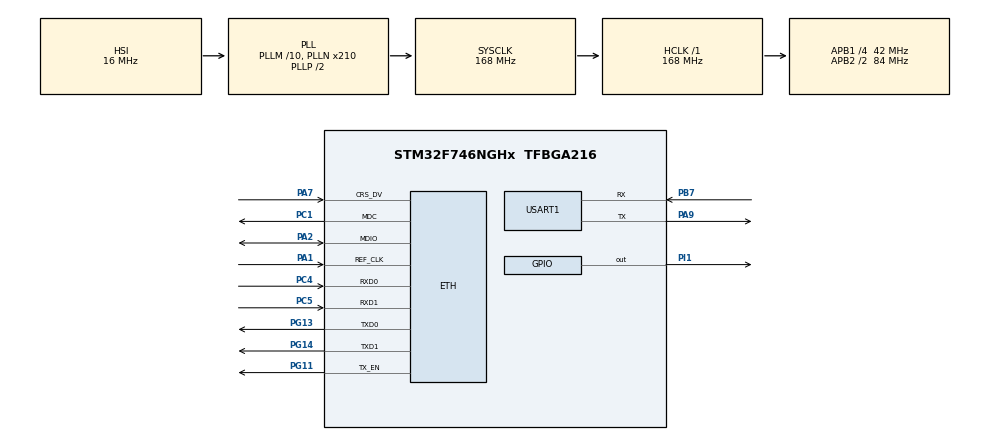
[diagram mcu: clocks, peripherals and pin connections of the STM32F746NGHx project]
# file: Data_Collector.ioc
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ETH.MediaInterface=HAL_ETH_RMII_MODE
FREERTOS.Tasks01=AppControlTask,24,1536,StartAppControlTask,Default,NULL,Dynamic,NULL,NULL;MonitorTask,8,512,StartMonitorTask,Default,NULL,Dynamic,NULL,NULL
FREERTOS.configUSE_NEWLIB_REENTRANT=1
LWIP.BSP.number=1
LWIP.CHECKSUM_BY_HARDWARE=1
LWIP.CHECKSUM_CHECK_ICMP=0
LWIP.CHECKSUM_CHECK_IP=0
LWIP.CHECKSUM_CHECK_TCP=0
LWIP.CHECKSUM_CHECK_UDP=0
LWIP.CHECKSUM_GEN_ICMP=0
LWIP.CHECKSUM_GEN_IP=0
LWIP.CHECKSUM_GEN_TCP=0
LWIP.CHECKSUM_GEN_UDP=0
LWIP.GATEWAY_ADDRESS=192.168.001.001
LWIP.IP_ADDRESS=192.168.001.050
LWIP.LWIP_DHCP=0
LWIP.MEM_SIZE=1600
LWIP.NETMASK_ADDRESS=255.255.255.000
LWIP.TCPIP_THREAD_STACKSIZE=1024
LWIP.Version=v2.1.2_Cube
LWIP0.BSP.STBoard=false
LWIP0.BSP.api=BSP_COMPONENT_DRIVER
LWIP0.BSP.component=LAN8742
LWIP0.BSP.instance=LAN8742
LWIP0.BSP.name=Driver_PHY
LWIP0.BSP.semaphore=S_LAN8742
LWIP0.BSP.solution=LAN8742
Mcu.Family=STM32F7
Mcu.Name=STM32F746NGHx
Mcu.Package=TFBGA216
NVIC.ETH_IRQn=true\:5\:0\:false\:false\:true\:true\:false\:true\:true
NVIC.PriorityGroup=NVIC_PRIORITYGROUP_4
NVIC.TIM6_DAC_IRQn=true\:15\:0\:false\:false\:true\:false\:false\:true\:true
NVIC.TimeBase=TIM6_DAC_IRQn
NVIC.TimeBaseIP=TIM6
PA1.Mode=RMII
PA1.Signal=ETH_REF_CLK
PA13.Mode=Serial_Wire
PA13.Signal=SYS_JTMS-SWDIO
PA14.Mode=Serial_Wire
PA14.Signal=SYS_JTCK-SWCLK
PA2.Mode=RMII
PA2.Signal=ETH_MDIO
PA7.Mode=RMII
PA7.Signal=ETH_CRS_DV
PA9.Mode=Asynchronous
PA9.Signal=USART1_TX
PB7.Mode=Asynchronous
PB7.Signal=USART1_RX
PC1.Mode=RMII
PC1.Signal=ETH_MDC
PC4.Mode=RMII
PC4.Signal=ETH_RXD0
PC5.Mode=RMII
PC5.Signal=ETH_RXD1
PG11.Mode=RMII
PG11.Signal=ETH_TX_EN
PG13.Mode=RMII
PG13.Signal=ETH_TXD0
PG14.Mode=RMII
PG14.Signal=ETH_TXD1
PH0/OSC_IN.Mode=HSE-External-Oscillator
PH0/OSC_IN.Signal=RCC_OSC_IN
PH1/OSC_OUT.Mode=HSE-External-Oscillator
PH1/OSC_OUT.Signal=RCC_OSC_OUT
PI1.Signal=GPIO_Output
ProjectManager.HeapSize=0x200
ProjectManager.StackSize=0x400
ProjectManager.TargetToolchain=STM32CubeIDE
RCC.AHBFreq_Value=168000000
RCC.APB1CLKDivider=RCC_HCLK_DIV4
RCC.APB1Freq_Value=42000000
RCC.APB1TimFreq_Value=84000000
RCC.APB2CLKDivider=RCC_HCLK_DIV2
RCC.APB2Freq_Value=84000000
RCC.APB2TimFreq_Value=168000000
RCC.CortexFreq_Value=168000000
RCC.HCLKFreq_Value=168000000
RCC.HSE_VALUE=25000000
RCC.HSI_VALUE=16000000
RCC.LSE_VALUE=32768
RCC.PLLM=10
RCC.PLLN=210
RCC.PLLSourceVirtual=RCC_PLLSOURCE_HSI
RCC.SYSCLKFreq_VALUE=168000000
RCC.SYSCLKSource=RCC_SYSCLKSOURCE_PLLCLK
RCC.USBFreq_Value=168000000
RCC.VCOOutputFreq_Value=336000000
TIM2.Prescaler=21599
USART1.VirtualMode-Asynchronous=VM_ASYNC
VP_CRC_VS_CRC.Mode=CRC_Activate
VP_FREERTOS_VS_CMSIS_V2.Mode=CMSIS_V2
VP_LWIP_VS_Enabled.Mode=Enabled
VP_SYS_VS_tim6.Mode=TIM6
VP_TIM2_VS_ClockSourceINT.Mode=Internal
board=STM32F746G-DISCO

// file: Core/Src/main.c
/* USER CODE BEGIN Header */
/**
  ******************************************************************************
  * @file           : main.c
  * @brief          : Main program body
  ******************************************************************************
  * @attention
  *
  * Copyright (c) 2026 STMicroelectronics.
  * All rights reserved.
  *
  * This software is licensed under terms that can be found in the LICENSE file
  * in the root directory of this software component.
  * If no LICENSE file comes with this software, it is provided AS-IS.
  *
  ******************************************************************************
  */
/* USER CODE END Header */
#include "main.h"
#include "cmsis_os.h"
#include "crc.h"
#include "lwip.h"
#include "tim.h"
#include "usart.h"
#include "gpio.h"

/* USER CODE BEGIN Includes */
#include <stdio.h>
#include "svc_monitoring.h"
/* USER CODE END Includes */

void SystemClock_Config(void);
void MX_FREERTOS_Init(void);

/* USER CODE BEGIN 0 */
int _write(int file, char *ptr, int len)
{
  HAL_UART_Transmit(&huart1, (const uint8_t *)ptr, len, HAL_MAX_DELAY);

  return len;
}
/* USER CODE END 0 */

int main(void)
{

  /* MCU Configuration--------------------------------------------------------*/

  /* Reset of all peripherals, Initializes the Flash interface and the Systick. */
  HAL_Init();

  /* Configure the system clock */
  SystemClock_Config();

  /* Initialize all configured peripherals */
  MX_GPIO_Init();
  MX_USART1_UART_Init();
  MX_TIM2_Init();
  MX_CRC_Init();
  /* USER CODE BEGIN 2 */
  printf("[INIT] STM32F746G Initilization...\r\n");

  HAL_TIM_Base_Start(&htim2);
  /* USER CODE END 2 */

  /* Init scheduler */
  osKernelInitialize();  /* Call init function for freertos objects (in cmsis_os2.c) */
  MX_FREERTOS_Init();

  /* Start scheduler */
  osKernelStart();

  /* We should never get here as control is now taken by the scheduler */

  /* Infinite loop */
  while (1)
  {

  }
}

void SystemClock_Config(void)
{
  RCC_OscInitTypeDef RCC_OscInitStruct = {0};
  RCC_ClkInitTypeDef RCC_ClkInitStruct = {0};

  /** Configure the main internal regulator output voltage
  */
  __HAL_RCC_PWR_CLK_ENABLE();
  __HAL_PWR_VOLTAGESCALING_CONFIG(PWR_REGULATOR_VOLTAGE_SCALE2);

  /** Initializes the RCC Oscillators according to the specified parameters
  * in the RCC_OscInitTypeDef structure.
  */
  RCC_OscInitStruct.OscillatorType = RCC_OSCILLATORTYPE_HSI;
  RCC_OscInitStruct.HSIState = RCC_HSI_ON;
  RCC_OscInitStruct.HSICalibrationValue = RCC_HSICALIBRATION_DEFAULT;
  RCC_OscInitStruct.PLL.PLLState = RCC_PLL_ON;
  RCC_OscInitStruct.PLL.PLLSource = RCC_PLLSOURCE_HSI;
  RCC_OscInitStruct.PLL.PLLM = 10;
  RCC_OscInitStruct.PLL.PLLN = 210;
  RCC_OscInitStruct.PLL.PLLP = RCC_PLLP_DIV2;
  RCC_OscInitStruct.PLL.PLLQ = 2;
  if (HAL_RCC_OscConfig(&RCC_OscInitStruct) != HAL_OK)
  {
    Error_Handler();
  }

  /** Initializes the CPU, AHB and APB buses clocks
  */
  RCC_ClkInitStruct.ClockType = RCC_CLOCKTYPE_HCLK|RCC_CLOCKTYPE_SYSCLK
                              |RCC_CLOCKTYPE_PCLK1|RCC_CLOCKTYPE_PCLK2;
  RCC_ClkInitStruct.SYSCLKSource = RCC_SYSCLKSOURCE_PLLCLK;
  RCC_ClkInitStruct.AHBCLKDivider = RCC_SYSCLK_DIV1;
  RCC_ClkInitStruct.APB1CLKDivider = RCC_HCLK_DIV4;
  RCC_ClkInitStruct.APB2CLKDivider = RCC_HCLK_DIV2;

  if (HAL_RCC_ClockConfig(&RCC_ClkInitStruct, FLASH_LATENCY_5) != HAL_OK)
  {
    Error_Handler();
  }
}

void HAL_TIM_PeriodElapsedCallback(TIM_HandleTypeDef *htim)
{
  if (htim->Instance == TIM6)
  {
    HAL_IncTick();
  }
}

void Error_Handler(void)
{
  __disable_irq();
  while (1)
  {
  }
}

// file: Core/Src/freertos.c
/* USER CODE BEGIN Header */
/**
  ******************************************************************************
  * File Name          : freertos.c
  * Description        : Code for freertos applications
  ******************************************************************************
  * @attention
  *
  * Copyright (c) 2026 STMicroelectronics.
  * All rights reserved.
  *
  * This software is licensed under terms that can be found in the LICENSE file
  * in the root directory of this software component.
  * If no LICENSE file comes with this software, it is provided AS-IS.
  *
  ******************************************************************************
  */
/* USER CODE END Header */

#include "FreeRTOS.h"
#include "task.h"
#include "main.h"
#include "cmsis_os.h"

/* USER CODE BEGIN Includes */
#include "app_control.h"
#include "task_monitoring.h"
/* USER CODE END Includes */

/* Definitions for AppControlTask */
osThreadId_t AppControlTaskHandle;
const osThreadAttr_t AppControlTask_attributes = {
  .name = "AppControlTask",
  .stack_size = 1536 * 4,
  .priority = (osPriority_t) osPriorityNormal,
};
/* Definitions for MonitorTask */
osThreadId_t MonitorTaskHandle;
const osThreadAttr_t MonitorTask_attributes = {
  .name = "MonitorTask",
  .stack_size = 1024 * 4,
  .priority = (osPriority_t) osPriorityLow,
};

void StartAppControlTask(void *argument);
void StartMonitorTask(void *argument);

extern void MX_LWIP_Init(void);
void MX_FREERTOS_Init(void); /* (MISRA C 2004 rule 8.1) */

void MX_FREERTOS_Init(void) {

  /* Create the thread(s) */
  /* creation of AppControlTask */
  AppControlTaskHandle = osThreadNew(StartAppControlTask, NULL, &AppControlTask_attributes);

  /* creation of MonitorTask */
  MonitorTaskHandle = osThreadNew(StartMonitorTask, NULL, &MonitorTask_attributes);

}

void StartAppControlTask(void *argument)
{
  /* init code for LWIP */
  MX_LWIP_Init();
  /* USER CODE BEGIN StartAppControlTask */

  AppControlTask(argument);
  /* Infinite loop */
  for(;;)
  {
    osDelay(1);
  }
  /* USER CODE END StartAppControlTask */
}

void StartMonitorTask(void *argument)
{
  /* USER CODE BEGIN StartMonitorTask */

  MonitorTask(argument);
  /* Infinite loop */
  for(;;)
  {
    osDelay(1);
  }
  /* USER CODE END StartMonitorTask */
}
